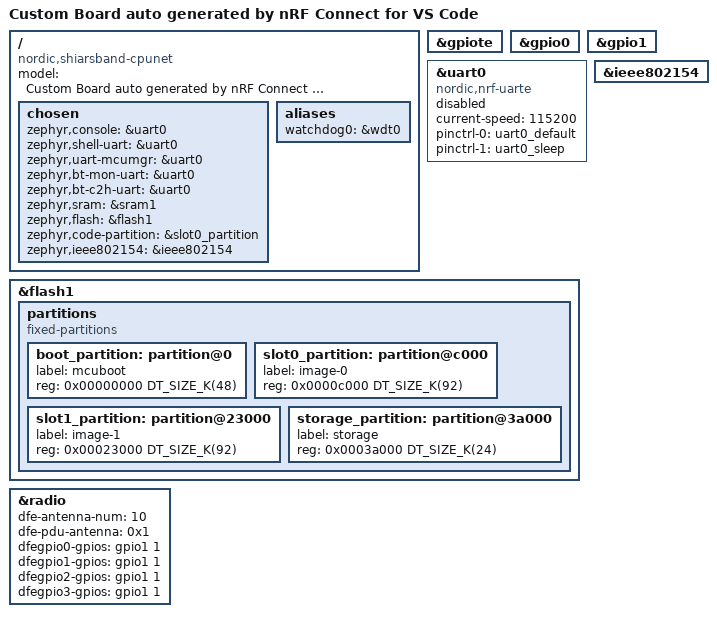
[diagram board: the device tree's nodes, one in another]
/dts-v1/;
#include <nordic/nrf5340_cpunet_qkaa.dtsi>
#include "shiarsband_common-pinctrl.dtsi"

/ {
	model = "Custom Board auto generated by nRF Connect for VS Code";
	compatible = "nordic,shiarsband-cpunet";

	chosen {
		zephyr,console = &uart0;
		zephyr,shell-uart = &uart0;
		zephyr,uart-mcumgr = &uart0;
		zephyr,bt-mon-uart = &uart0;
		zephyr,bt-c2h-uart = &uart0;
		zephyr,sram = &sram1;
		zephyr,flash = &flash1;
		zephyr,code-partition = &slot0_partition;
		zephyr,ieee802154 = &ieee802154;
	};
	/* These aliases are provided for compatibility with samples */
	aliases {
		watchdog0 = &wdt0;
	};
};

&gpiote {
	status = "okay";
};

&gpio0 {
	status = "okay";
};

&gpio1 {
	status = "okay";
};

&uart0 {
	compatible = "nordic,nrf-uarte";
	status = "disabled";
	// status = "okay";
	current-speed = <115200>;
	pinctrl-0 = <&uart0_default>;
	pinctrl-1 = <&uart0_sleep>;
	pinctrl-names = "default", "sleep";
};

&flash1 {
	partitions {
		compatible = "fixed-partitions";
		#address-cells = <1>;
		#size-cells = <1>;

		boot_partition: partition@0 {
			label = "mcuboot";
			reg = <0x00000000 DT_SIZE_K(48)>;
		};

		slot0_partition: partition@c000 {
			label = "image-0";
			reg = <0x0000c000 DT_SIZE_K(92)>;
		};

		slot1_partition: partition@23000 {
			label = "image-1";
			reg = <0x00023000 DT_SIZE_K(92)>;
		};

		storage_partition: partition@3a000 {
			label = "storage";
			reg = <0x0003a000 DT_SIZE_K(24)>;
		};
	};
};

&ieee802154 {
	status = "okay";
};

// Zephyr gets mad if this is not set, even thought we don't do any switching
&radio {
	status = "okay";
	dfe-antenna-num = <10>;
	dfe-pdu-antenna = <0x1>;
	dfegpio0-gpios = <&gpio1 1 0>;
	dfegpio1-gpios = <&gpio1 1 0>;
	dfegpio2-gpios = <&gpio1 1 0>;
	dfegpio3-gpios = <&gpio1 1 0>;
};


#include "shiarsband-shared_sram.dtsi"
